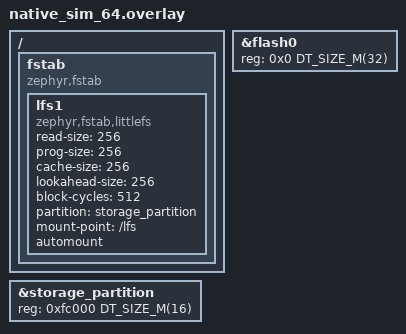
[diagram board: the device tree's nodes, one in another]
/ {
	fstab {
		compatible = "zephyr,fstab";
		lfs1: lfs1 {
			compatible = "zephyr,fstab,littlefs";
			read-size = <256>;
			prog-size = <256>;
			cache-size = <256>;
			lookahead-size = <256>;
			block-cycles = <512>;
			partition = <&storage_partition>;
			mount-point = "/lfs";
			automount;
		};
	};
};

&flash0 {
	reg = < 0x0 DT_SIZE_M(32) >;
};

&storage_partition {
    reg = < 0xfc000 DT_SIZE_M(16) >;
};
